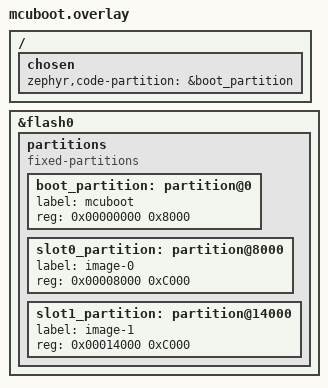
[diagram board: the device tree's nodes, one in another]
/ {
    chosen {
        zephyr,code-partition = &boot_partition;
    };
};

&flash0 {
    /delete-node/ partitions;

    partitions {
        compatible = "fixed-partitions";
        #address-cells = <1>;
        #size-cells = <1>;

        boot_partition: partition@0 {
            label = "mcuboot";
            reg = <0x00000000 0x8000>;
        };
        slot0_partition: partition@8000 {
            label = "image-0";
            reg = <0x00008000 0xC000>;
        };
        slot1_partition: partition@14000 {
            label = "image-1";
            reg = <0x00014000 0xC000>;
        };
    };
};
